# STM32WL54xx register map
File version: 1.0
Registers are 32-bit, read-write, reset 0x0 unless marked. A register's access mark holds for its fields unless they carry their own. Offsets are from the block's base; [hi:lo] are bit positions; {n}, {i} and the like mark numbered series; 'fields as' and 'values as' point back to an identical list.

## DMA1
Base 0x40020000
Same registers: DMA2 0x40020400
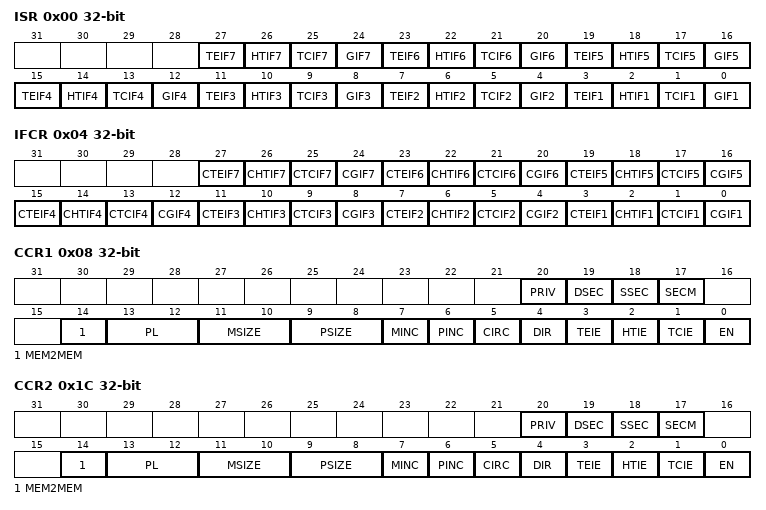
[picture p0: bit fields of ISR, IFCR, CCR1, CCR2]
0x00 ISR — DMA interrupt status register
  [4n-1] TEIF{n} (n=1..7) — Channel {n} Transfer Error flag
  [4n-2] HTIF{n} (n=1..7) — Channel {n} Half Transfer flag
  [4n-3] TCIF{n} (n=1..7) — Channel {n} Transfer Complete flag
  [4n-4] GIF{n} (n=1..7) — Channel {n} Global interrupt flag
0x04 IFCR — DMA interrupt flag clear register
  [4n-1] CTEIF{n} (n=1..7) — Channel {n} Transfer Error clear
  [4n-2] CHTIF{n} (n=1..7) — Channel {n} Half Transfer clear
  [4n-3] CTCIF{n} (n=1..7) — Channel {n} Transfer Complete clear
  [4n-4] CGIF{n} (n=1..7) — Channel {n} Global interrupt clear
0x08 CCR1 — DMA channel x configuration register
  [20] PRIV — Privileged mode
  [19] DSEC — Security of the DMA transfer to the destination, only accessible write, read by CM0PLUS
  [18] SSEC — Security of the DMA transfer from the source, only accessible write, read by CM0PLUS
  [17] SECM — Secure mode
  [14] MEM2MEM — Memory to memory mode
  [13:12] PL — PL[1:0] bits(Channel Priority level)
  [11:10] MSIZE — MSIZE[1:0] bits (Memory size)
  [9:8] PSIZE — PSIZE[1:0] bits (Peripheral size)
  [7] MINC — Memory increment mode
  [6] PINC — Peripheral increment mode
  [5] CIRC — Circular mode
  [4] DIR — Data transfer direction
  [3] TEIE — Transfer error interrupt enable
  [2] HTIE — Half Transfer interrupt enable
  [1] TCIE — Transfer complete interrupt enable
  [0] EN — Channel enable
0x0C CNDTR1 — DMA channel x number of data register
  [17:0] NDT — Number of data to Transfer
0x10 CPAR1 — DMA channel x peripheral address register
  [31:0] PA — Peripheral Address
{0x0+0x14*i} CMAR{i} (i=1..7) — DMA channel x memory address register
  [31:0] MA — Memory Address
0x1C CCR2 — DMA channel x configuration register
  fields as CCR1
0x20 CNDTR2 — DMA channel x number of data register
  [17:0] NDT — Number of data to Transfer
0x24 CPAR2 — DMA channel x peripheral address register
  [31:0] PA — Peripheral Address
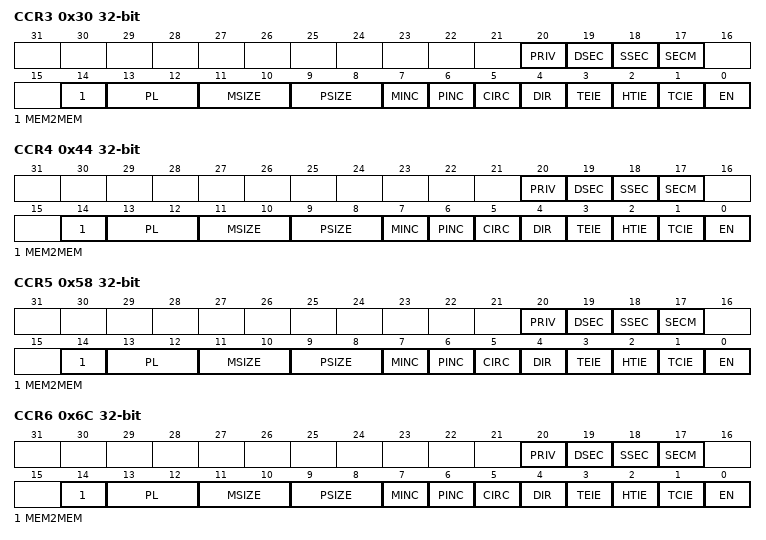
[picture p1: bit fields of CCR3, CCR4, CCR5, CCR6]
0x30 CCR3 — DMA channel x configuration register
  fields as CCR1
0x34 CNDTR3 — DMA channel x number of data register
  [17:0] NDT — Number of data to Transfer
0x38 CPAR3 — DMA channel x peripheral address register
  [31:0] PA — Peripheral Address
0x44 CCR4 — DMA channel x configuration register
  fields as CCR1
0x48 CNDTR4 — DMA channel x number of data register
  [17:0] NDT — Number of data to Transfer
0x4C CPAR4 — DMA channel x peripheral address register
  [31:0] PA — Peripheral Address
0x58 CCR5 — DMA channel x configuration register
  fields as CCR1
0x5C CNDTR5 — DMA channel x number of data register
  [17:0] NDT — Number of data to Transfer
0x60 CPAR5 — DMA channel x peripheral address register
  [31:0] PA — Peripheral Address
0x6C CCR6 — DMA channel x configuration register
  fields as CCR1
0x70 CNDTR6 — DMA channel x number of data register
  [17:0] NDT — Number of data to Transfer
0x74 CPAR6 — DMA channel x peripheral address register
  [31:0] PA — Peripheral Address
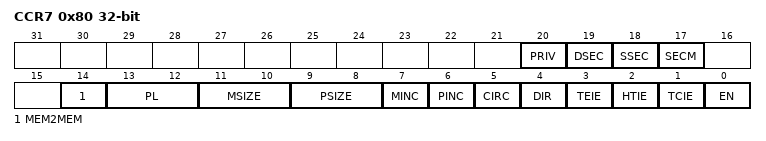
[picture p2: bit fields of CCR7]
0x80 CCR7 — DMA channel x configuration register
  fields as CCR1
0x84 CNDTR7 — DMA channel x number of data register
  [17:0] NDT — Number of data to Transfer
0x88 CPAR7 — DMA channel x peripheral address register
  [31:0] PA — Peripheral Address

## DMAMUX1 — DMA Multiplexer
Base 0x40020800
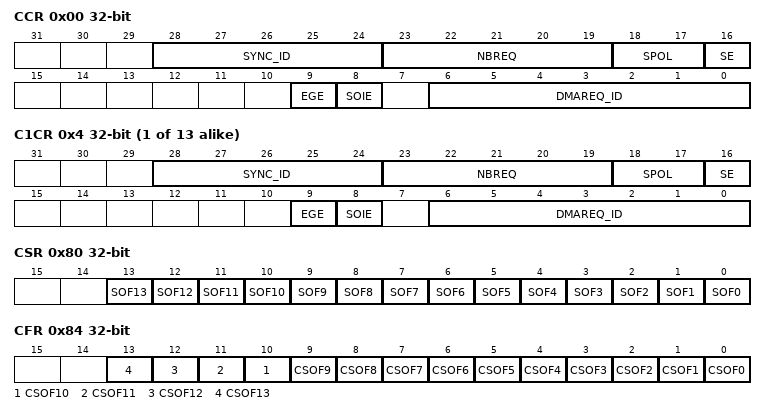
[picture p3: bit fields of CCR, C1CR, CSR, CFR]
0x00 CCR — DMA Multiplexer Channel x Control Register
  [28:24] SYNC_ID — Synchronization ID
  [23:19] NBREQ — Number of request
  [18:17] SPOL — Synchronization polarity
  [16] SE — Synchronization enable
  [9] EGE — Event generation interrupt enable
  [8] SOIE — Synchro overrun interrupt enable
  [6:0] DMAREQ_ID — DMA Request ID
{0x0+4i} C{i}CR (i=1..13) — DMA Multiplexer Channel x Control Register
  fields as CCR
0x80 CSR — DMA Channel Status Register
  [n] SOF{n} (n=0..13) — Synchronization Overrun Flag {n}
0x84 CFR — DMA Channel Clear Flag Register
  [n] CSOF{n} (n=0..13) — Clear Overrun Flag {n}
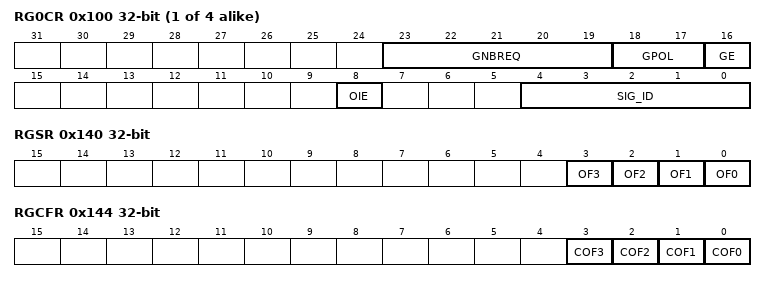
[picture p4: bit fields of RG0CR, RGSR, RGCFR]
{0x100+4i} RG{i}CR (i=0..3) — DMA Request Generator x Control Register
  [23:19] GNBREQ — Number of request
  [18:17] GPOL — Generation polarity
  [16] GE — Generation enable
  [8] OIE — Overrun interrupt enable
  [4:0] SIG_ID — Signal ID
0x140 RGSR — DMA Request Generator Status Register
  [n] OF{n} (n=0..3) — Overrun flag {n}
0x144 RGCFR — DMA Request Generator Clear Flag Register
  [n] COF{n} (n=0..3) — Clear Overrun flag {n}
